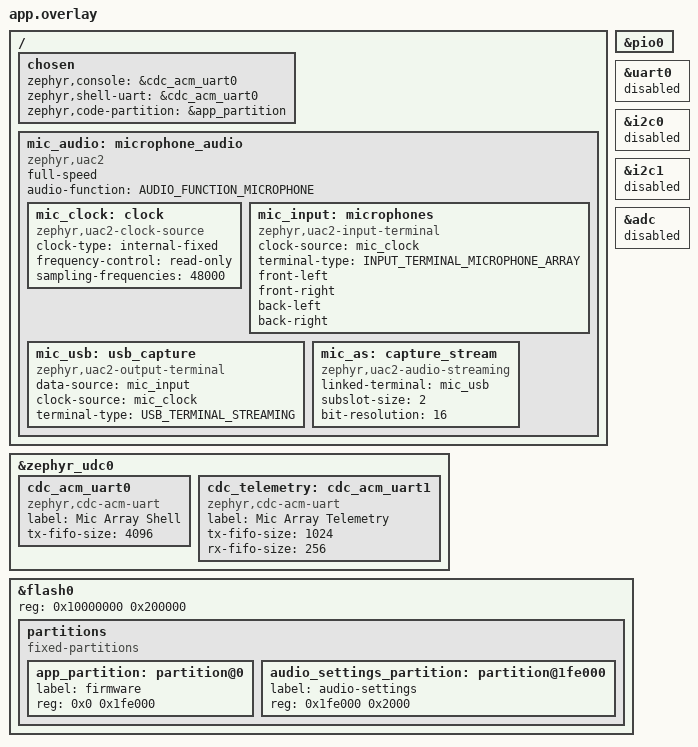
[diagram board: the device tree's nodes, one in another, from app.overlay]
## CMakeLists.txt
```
cmake_minimum_required(VERSION 3.20.0)
find_package(Zephyr REQUIRED HINTS $ENV{ZEPHYR_BASE})
project(pico2_mic_array)
target_include_directories(app PRIVATE src)
target_sources(app PRIVATE src/doa.c src/doa_control.c src/telemetry.c)
target_sources(app PRIVATE src/main.c src/dsp_parallel.c src/beamform.c src/noise_reduce.c src/nr_control.c src/usb_audio.c src/stream.c src/capture.c src/pdm_filter.c)

target_link_libraries(app PRIVATE m)

target_sources(app PRIVATE src/audio_settings.c)
```

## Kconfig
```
mainmenu "RP2354A microphone array"
source "Kconfig.zephyr"

config PICOSDK_USE_DMA
	default y
```

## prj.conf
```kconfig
CONFIG_GPIO=y
CONFIG_PIO_RPI_PICO=y
# The application owns the DMA controller: the generic driver cannot chain blocks.
CONFIG_DMA=n
CONFIG_USB_DEVICE_STACK_NEXT=y
CONFIG_UART_LINE_CTRL=y
CONFIG_SHELL=y
CONFIG_SHELL_BACKEND_SERIAL=y
CONFIG_SHELL_VT100_COLORS=n
CONFIG_SHELL_STACK_SIZE=4096
CONFIG_SHELL_BACKEND_SERIAL_TX_RING_BUFFER_SIZE=4096
# Emit machine telemetry in large batches rather than 30-byte printf fragments.
CONFIG_SHELL_PRINTF_BUFF_SIZE=512
CONFIG_MAIN_STACK_SIZE=4096
CONFIG_SPEED_OPTIMIZATIONS=y
CONFIG_BUILD_OUTPUT_UF2=y
# Keep capture/USB fault counters, but omit debug-only kernel assertions and
# spinlock ownership checks from the real-time audio build.
CONFIG_ASSERT=n
CONFIG_SPIN_VALIDATE=n

CONFIG_CRC=y

# Batch full-speed USB packets to reduce per-transfer workqueue overhead.
CONFIG_USBD_CDC_ACM_BUF_POOL=y
CONFIG_USBD_CDC_ACM_BUF_POOL_SIZE=1024
CONFIG_CDC_ACM_SERIAL_INITIALIZE_AT_BOOT=n
CONFIG_USBD_AUDIO2_CLASS=y

CONFIG_FPU=y
CONFIG_FPU_SHARING=y

CONFIG_FLASH=y
CONFIG_USE_DT_CODE_PARTITION=y
CONFIG_REBOOT=y
```

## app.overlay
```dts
#include <zephyr/dt-bindings/usb/audio.h>
/ {
	chosen {
		zephyr,console = &cdc_acm_uart0;
		zephyr,shell-uart = &cdc_acm_uart0;
	};
};

&zephyr_udc0 {
	cdc_acm_uart0: cdc_acm_uart0 {
		compatible = "zephyr,cdc-acm-uart";
		label = "Mic Array Shell";
		tx-fifo-size = <4096>;
	};
	cdc_telemetry: cdc_acm_uart1 {
		compatible = "zephyr,cdc-acm-uart";
		label = "Mic Array Telemetry";
		tx-fifo-size = <1024>;
		rx-fifo-size = <256>;
	};
};

mic_pio: &pio0 { status = "okay"; };
/* RP2354A: GP6=SCLK, GP7-GP10=DATA1-4, GP11-GP13=DIN/BCLK/LRC (U7). */
&uart0 { status = "disabled"; };
&i2c0 { status = "disabled"; };
&i2c1 { status = "disabled"; };
&adc { status = "disabled"; };

/ {
 mic_audio: microphone_audio {
  compatible = "zephyr,uac2";
  full-speed;
  audio-function = <AUDIO_FUNCTION_MICROPHONE>;
  mic_clock: clock {
   compatible = "zephyr,uac2-clock-source";
   clock-type = "internal-fixed";
   frequency-control = "read-only";
   sampling-frequencies = <48000>;
  };
  mic_input: microphones {
   compatible = "zephyr,uac2-input-terminal";
   clock-source = <&mic_clock>;
   terminal-type = <INPUT_TERMINAL_MICROPHONE_ARRAY>;
   /* USB quad channel slots; not physical array coordinates. */
   front-left;
   front-right;
   back-left;
   back-right;
  };
  mic_usb: usb_capture {
   compatible = "zephyr,uac2-output-terminal";
   data-source = <&mic_input>;
   clock-source = <&mic_clock>;
   terminal-type = <USB_TERMINAL_STREAMING>;
  };
  mic_as: capture_stream {
   compatible = "zephyr,uac2-audio-streaming";
   linked-terminal = <&mic_usb>;
   subslot-size = <2>;
   bit-resolution = <16>;
  };
 };
};

/ { chosen { zephyr,code-partition = &app_partition; }; };
/* RP2354A has 2 MiB in-package flash; reserve the final 8 KiB for settings. */
&flash0 {
 reg = <0x10000000 0x200000>;
 ranges = <0x0 0x10000000 0x200000>;
 partitions {
  compatible = "fixed-partitions";
  #address-cells = <1>; #size-cells = <1>;
  app_partition: partition@0 { label = "firmware"; reg = <0x0 0x1fe000>; };
  audio_settings_partition: partition@1fe000 { label = "audio-settings"; reg = <0x1fe000 0x2000>; };
 };
};
```

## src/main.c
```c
#include "capture.h"
#include "board_pins.h"
#include "pdm_filter.h"
#include "dsp_parallel.h"
#include "speaker_tone.h"
#include "stream.h"
#include "usb_audio.h"
#include "nr_control.h"
#include "doa.h"
#include <zephyr/shell/shell.h>
#include <pico/bootrom.h>
#include <zephyr/drivers/misc/pio_rpi_pico/pio_rpi_pico.h>
#include <hardware/clocks.h>
#include <hardware/timer.h>
#include <hardware/dma.h>
#include <hardware/pio_instructions.h>
#include <stdlib.h>
#include <string.h>

#define MAX_RECORD_FRAMES 16000
static struct pdm_filter filter;
static int16_t pcm[CAPTURE_FRAMES * MIC_CHANNELS];

#define RAW_BLOCKS 4
static union {
 int16_t recording[MAX_RECORD_FRAMES * MIC_CHANNELS];
 struct { uint32_t words[RAW_BLOCKS * CAPTURE_WORDS];
          int16_t pcm[RAW_BLOCKS * CAPTURE_FRAMES * MIC_CHANNELS]; } raw;
} diagnostic;
#define recording diagnostic.recording
#define raw_snapshot diagnostic.raw.words
#define raw_pcm diagnostic.raw.pcm
static atomic_t raw_request;
static unsigned raw_blocks;
static struct k_spinlock state_lock;
static struct {
	uint32_t target;
	uint32_t frames;
	uint32_t peak[MIC_CHANNELS];
	uint32_t max_process_us;
	uint32_t filter_blocks; uint64_t filter_total_us;
	bool ready;
	bool invalid;
} state;

static int cmd_boot(const struct shell *sh, size_t argc, char **argv)
{
	ARG_UNUSED(argc); ARG_UNUSED(argv);
	shell_print(sh, "Rebooting into USB BOOTSEL mode...");
	/* Allow the USB shell message to drain before disconnecting. */
	k_msleep(100);
	/* No activity GPIO; enable both mass-storage and picoboot interfaces. */
	reset_usb_boot(0, 0);
}

SHELL_CMD_ARG_REGISTER(boot, NULL, "Reboot into USB BOOTSEL mode for UF2 flashing",
		       cmd_boot, 1, 0);

static uint32_t i2s_probe[2048];
#if AUDIO_SPEAKER_DIAGNOSTICS
static uint32_t speaker_samples[32000];

/* Sample the actual output GPIOs internally, without adding jumper wires.
 * Each word packs eight chronological {LRCLK,BCLK,DIN} triples, MSB first. */
static int probe_init(PIO pio, size_t *probe_sm)
{
	const struct device *dev = DEVICE_DT_GET(DT_NODELABEL(mic_pio));
	int ret = pio_rpi_pico_allocate_sm(dev, probe_sm);
	if (ret) { return ret; }
	uint16_t instructions[] = {
		pio_encode_wait_gpio(false, SPEAKER_BCLK_PIN),
		pio_encode_wait_gpio(true, SPEAKER_BCLK_PIN),
		pio_encode_in(pio_pins, 3),
	};
	struct pio_program program = {.instructions = instructions, .length = 3, .origin = -1};
	if (!pio_can_add_program(pio, &program)) {
		pio_sm_unclaim(pio, *probe_sm);
		return -ENOMEM;
	}
	unsigned offset = pio_add_program(pio, &program);
	pio_sm_config config = pio_get_default_sm_config();
	sm_config_set_wrap(&config, offset, offset + 2);
	sm_config_set_in_pins(&config, SPEAKER_DATA_PIN);
	sm_config_set_in_shift(&config, false, true, 24);
	sm_config_set_fifo_join(&config, PIO_FIFO_JOIN_RX);
	pio_sm_init(pio, *probe_sm, offset, &config);
	return 0;
}

static int cmd_speaker_test(const struct shell *sh, size_t argc, char **argv)
{
	bool verify = strcmp(argv[0], "verify") == 0;
	unsigned frequency = 500;
	unsigned peak = 512;
	bool left_justified = false;
	if (argc > 1) {
		char *end;
		frequency = strtoul(argv[1], &end, 10);
		if (*end || frequency < 200 || frequency > 2000) { return -EINVAL; }
	}
	if (argc > 2) {
		char *end;
		peak = strtoul(argv[2], &end, 10);
		if (*end || peak > 512) { return -EINVAL; }
	}
	if (argc > 3) {
		if (strcmp(argv[3], "left") == 0) { left_justified = true; }
		else if (strcmp(argv[3], "i2s") != 0) { return -EINVAL; }
	}
	static bool initialized;
	static size_t speaker_sm;
	static unsigned format_offset[2];
	static bool probe_initialized;
	static size_t probe_sm;
	const struct device *dev = DEVICE_DT_GET(DT_NODELABEL(mic_pio));
	if (!device_is_ready(dev) || !atomic_get(&capture_stats.blocks)) {
		shell_error(sh, "Audio hardware not initialized");
		return -ENODEV;
	}
	PIO pio = pio_rpi_pico_get_pio(dev);
	if (!initialized) {
		int ret = pio_rpi_pico_allocate_sm(dev, &speaker_sm);
		if (ret) { return ret; }
		/* 32-bit stereo I2S. LR changes on the previous channel's LSB,
		 * one BCLK before the next MSB. Side-set bit0=BCLK, bit1=LRCLK. */
		uint16_t instructions[] = {
			pio_encode_out(pio_pins, 1) | pio_encode_sideset(2, 0),
			pio_encode_jmp_x_dec(0) | pio_encode_sideset(2, 1),
			pio_encode_out(pio_pins, 1) | pio_encode_sideset(2, 2),
			pio_encode_set(pio_x, 30) | pio_encode_sideset(2, 3),
			pio_encode_out(pio_pins, 1) | pio_encode_sideset(2, 2),
			pio_encode_jmp_x_dec(4) | pio_encode_sideset(2, 3),
			pio_encode_out(pio_pins, 1) | pio_encode_sideset(2, 0),
			pio_encode_set(pio_x, 30) | pio_encode_sideset(2, 1),
		};
		struct pio_program program = {
			.instructions = instructions, .length = ARRAY_SIZE(instructions), .origin = -1,
		};
		if (!pio_can_add_program(pio, &program)) {
			pio_sm_unclaim(pio, speaker_sm);
			return -ENOMEM;
		}
		unsigned offset = pio_add_program(pio, &program);
		format_offset[0] = offset;
		/* Diagnostic alternate format: align LRCLK with the MSB, as used
		 * by MAX98357B. Keep separate programs so switching is explicit. */
		uint16_t left_instructions[] = {
			pio_encode_out(pio_pins, 1) | pio_encode_sideset(2, 0),
			pio_encode_set(pio_x, 30) | pio_encode_sideset(2, 1),
			pio_encode_out(pio_pins, 1) | pio_encode_sideset(2, 0),
			pio_encode_jmp_x_dec(2) | pio_encode_sideset(2, 1),
			pio_encode_out(pio_pins, 1) | pio_encode_sideset(2, 2),
			pio_encode_set(pio_x, 30) | pio_encode_sideset(2, 3),
			pio_encode_out(pio_pins, 1) | pio_encode_sideset(2, 2),
			pio_encode_jmp_x_dec(6) | pio_encode_sideset(2, 3),
		};
		struct pio_program left_program = {
			.instructions = left_instructions, .length = 8, .origin = -1,
		};
		if (!pio_can_add_program(pio, &left_program)) {
			pio_remove_program(pio, &program, offset);
			pio_sm_unclaim(pio, speaker_sm);
			return -ENOMEM;
		}
		format_offset[1] = pio_add_program(pio, &left_program);
		pio_sm_config config = pio_get_default_sm_config();
		sm_config_set_wrap(&config, offset, offset + 7);
		sm_config_set_out_pins(&config, SPEAKER_DATA_PIN, 1);
		sm_config_set_sideset(&config, 2, false, false);
		sm_config_set_sideset_pins(&config, SPEAKER_BCLK_PIN);
		sm_config_set_out_shift(&config, false, true, 32);
		sm_config_set_fifo_join(&config, PIO_FIFO_JOIN_TX);
		sm_config_set_clkdiv(&config, (float)clock_get_hz(clk_sys) / (16000u * 128u));
		for (unsigned pin = SPEAKER_DATA_PIN; pin <= SPEAKER_LRC_PIN; pin++) { pio_gpio_init(pio, pin); }
		pio_sm_init(pio, speaker_sm, offset, &config);
		pio_sm_set_consecutive_pindirs(pio, speaker_sm, SPEAKER_DATA_PIN, 3, true);
		initialized = true;
	}
	int channel = dma_claim_unused_channel(false);
	if (channel < 0) { return -EBUSY; }
	int probe_channel = -1;
	if (verify) {
		if (!probe_initialized) {
			int ret = probe_init(pio, &probe_sm);
			if (ret) { dma_channel_unclaim(channel); return ret; }
			probe_initialized = true;
		}
		probe_channel = dma_claim_unused_channel(false);
		if (probe_channel < 0) { dma_channel_unclaim(channel); return -EBUSY; }
		pio_sm_clear_fifos(pio, probe_sm);
		pio_sm_restart(pio, probe_sm);
		unsigned bottom = (pio->sm[probe_sm].execctrl & PIO_SM0_EXECCTRL_WRAP_BOTTOM_BITS) >>
				  PIO_SM0_EXECCTRL_WRAP_BOTTOM_LSB;
		pio_sm_exec(pio, probe_sm, pio_encode_jmp(bottom));
		dma_channel_config probe_config = dma_channel_get_default_config(probe_channel);
		channel_config_set_transfer_data_size(&probe_config, DMA_SIZE_32);
		channel_config_set_read_increment(&probe_config, false);
		channel_config_set_write_increment(&probe_config, true);
		channel_config_set_dreq(&probe_config, pio_get_dreq(pio, probe_sm, false));
		dma_channel_configure(probe_channel, &probe_config, i2s_probe,
				      &pio->rxf[probe_sm], ARRAY_SIZE(i2s_probe), true);
		pio_sm_set_enabled(pio, probe_sm, true);
	}
	/* Identical L/R preserves the module's mono mix. Fade both ends and
	 * finish with 8 ms of silence; default peak 512 is about -36 dBFS. */
	uint32_t phase = 0;
	uint32_t phase_step = ((uint64_t)frequency << 32) / 16000u;
	for (unsigned n = 0; n < 16000; n++, phase += phase_step) {
		uint16_t sample = (uint16_t)speaker_tone_sample(phase, n, peak);
		speaker_samples[2 * n] = (uint32_t)sample << 16;
		speaker_samples[2 * n + 1] = (uint32_t)sample << 16;
	}
	pio_sm_set_enabled(pio, speaker_sm, false);
	pio_sm_clear_fifos(pio, speaker_sm);
	pio_sm_restart(pio, speaker_sm);
	unsigned wrap = format_offset[left_justified];
	pio_sm_set_wrap(pio, speaker_sm, wrap, wrap + 7);
	pio_sm_exec(pio, speaker_sm, pio_encode_jmp(wrap));
	pio_sm_exec(pio, speaker_sm, pio_encode_set(pio_x, 30));
	pio_sm_set_pins_with_mask(pio, speaker_sm, 0, BIT(SPEAKER_DATA_PIN) | BIT(SPEAKER_BCLK_PIN) | BIT(SPEAKER_LRC_PIN));
	dma_channel_config dma_config = dma_channel_get_default_config(channel);
	channel_config_set_transfer_data_size(&dma_config, DMA_SIZE_32);
	channel_config_set_read_increment(&dma_config, true);
	channel_config_set_write_increment(&dma_config, false);
	channel_config_set_dreq(&dma_config, pio_get_dreq(pio, speaker_sm, true));
	shell_print(sh, "Playing %u Hz for 1 second; PCM16 peak=%u; format=%s...",
		    frequency, peak, left_justified ? "left" : "i2s");
	dma_channel_configure(channel, &dma_config, &pio->txf[speaker_sm],
			      speaker_samples, ARRAY_SIZE(speaker_samples), true);
	pio_sm_set_enabled(pio, speaker_sm, true);
	int64_t deadline = k_uptime_get() + 1500;
	while (dma_channel_is_busy(channel) && k_uptime_get() < deadline) { k_msleep(5); }
	bool timed_out = dma_channel_is_busy(channel);
	k_msleep(2); /* Drain the FIFO and final shift register. */
	pio_sm_set_enabled(pio, speaker_sm, false);
	dma_channel_cleanup(channel);
	dma_channel_unclaim(channel);
	pio_sm_set_pins_with_mask(pio, speaker_sm, 0, BIT(SPEAKER_DATA_PIN) | BIT(SPEAKER_BCLK_PIN) | BIT(SPEAKER_LRC_PIN));
	if (verify) {
		bool complete = !dma_channel_is_busy(probe_channel);
		pio_sm_set_enabled(pio, probe_sm, false);
		dma_channel_cleanup(probe_channel);
		dma_channel_unclaim(probe_channel);
		if (!complete) { shell_error(sh, "I2S probe did not complete"); return -EIO; }
		shell_print(sh, "I2S_BEGIN %u", (unsigned)ARRAY_SIZE(i2s_probe));
		for (unsigned i = 0; i < ARRAY_SIZE(i2s_probe); i += 8) {
			shell_print(sh, "%08x%08x%08x%08x%08x%08x%08x%08x",
				i2s_probe[i], i2s_probe[i+1], i2s_probe[i+2], i2s_probe[i+3],
				i2s_probe[i+4], i2s_probe[i+5], i2s_probe[i+6], i2s_probe[i+7]);
		}
		shell_print(sh, "I2S_END");
	}
	if (timed_out) {
		shell_error(sh, "Speaker DMA timed out");
		return -ETIMEDOUT;
	}
	shell_print(sh, "Speaker test complete");
	return 0;
}

SHELL_STATIC_SUBCMD_SET_CREATE(speaker_commands,
	SHELL_CMD_ARG(test, NULL, "Play tone [Hz=500] [peak=512; 0..512] [i2s|left]", cmd_speaker_test, 1, 3),
	SHELL_CMD_ARG(verify, NULL, "Play tone and export GPIO samples [Hz] [peak] [i2s|left]", cmd_speaker_test, 1, 3),
	SHELL_SUBCMD_SET_END);
SHELL_CMD_REGISTER(speaker, &speaker_commands, "MAX98357A speaker", NULL);
#endif

static int cmd_stats(const struct shell *sh, size_t argc, char **argv)
{
	ARG_UNUSED(argc); ARG_UNUSED(argv);
	k_spinlock_key_t key = k_spin_lock(&state_lock);
	uint32_t peaks[MIC_CHANNELS];
	memcpy(peaks, state.peak, sizeof(peaks));
	uint32_t max_us = state.max_process_us;
	uint32_t fb = state.filter_blocks; uint64_t ft = state.filter_total_us;
	bool ready = state.ready;
	k_spin_unlock(&state_lock, key);
	shell_print(sh, "rate=%u channels=4 ready=%u blocks=%ld dropped=%ld faults=%ld max_process_us=%u",
		capture_stats.sample_rate, ready, (long)atomic_get(&capture_stats.blocks),
		(long)atomic_get(&capture_stats.dropped), (long)atomic_get(&capture_stats.faults), max_us);
	shell_print(sh, "PDM_PROFILE blocks=%u mean_us=%u", fb, fb ? (unsigned)(ft/fb) : 0);
	uint32_t local_us,remote_us,worker_status;dsp_parallel_profile(&local_us,&remote_us,&worker_status);
	shell_print(sh,"DSP_PIPELINE cores=2 fir_core0_us=%u cic_core1_us=%u worker_status=%u",local_us,remote_us,worker_status);
	shell_print(sh, "peak_pcm16=%u,%u,%u,%u", peaks[0], peaks[1], peaks[2], peaks[3]);
	return 0;
}

static int cmd_record(const struct shell *sh, size_t argc, char **argv)
{
	ARG_UNUSED(argc);
	char *end;
	unsigned long ms = strtoul(argv[1], &end, 10);
	if (*end || ms < 1 || ms > MAX_RECORD_FRAMES * 1000u / PCM_SAMPLE_RATE) {
		shell_error(sh, "Duration must be 1..%u ms (RAM diagnostic limit)", MAX_RECORD_FRAMES * 1000u / PCM_SAMPLE_RATE);
		return -EINVAL;
	}
	k_spinlock_key_t key = k_spin_lock(&state_lock);
	if (!state.ready || atomic_get(&capture_stats.faults) ||
	    (!state.invalid && state.frames < state.target)) {
		k_spin_unlock(&state_lock, key);
		shell_error(sh, "Capture warming up, faulted, or recording busy");
		return -EBUSY;
	}
	state.frames = 0;
	state.target = MIN((uint64_t)ms * capture_stats.sample_rate / 1000u, MAX_RECORD_FRAMES);
	state.invalid = false;
	k_spin_unlock(&state_lock, key);
	shell_print(sh, "RECORDING");
	return 0;
}

static int cmd_status(const struct shell *sh, size_t argc, char **argv)
{
	ARG_UNUSED(argc); ARG_UNUSED(argv);
	k_spinlock_key_t key = k_spin_lock(&state_lock);
	uint32_t frames = state.frames, target = state.target;
	bool invalid = state.invalid;
	k_spin_unlock(&state_lock, key);
	shell_print(sh, "RECORD %s %u %u", invalid ? "INVALID" :
		(target == 0 ? "EMPTY" : (frames == target ? "DONE" : "BUSY")), frames, target);
	return 0;
}

static int cmd_dump(const struct shell *sh, size_t argc, char **argv)
{
	ARG_UNUSED(argc); ARG_UNUSED(argv);
	k_spinlock_key_t key = k_spin_lock(&state_lock);
	uint32_t frames = state.frames;
	bool valid = state.target && frames == state.target && !state.invalid;
	k_spin_unlock(&state_lock, key);
	if (!valid) {
		shell_error(sh, "No complete valid recording; use mic record <ms> then mic status");
		return -EAGAIN;
	}
	/* Shell commands are serialized. A new record command cannot overwrite
	 * this completed buffer while dump is running. Capture keeps running. */
	static const char hex[] = "0123456789abcdef";
	char line[257];
	const uint8_t *bytes = (const uint8_t *)recording;
	size_t length = frames * MIC_CHANNELS * sizeof(int16_t);
	shell_print(sh, "PCM_BEGIN %u 4 %u", capture_stats.sample_rate, frames);
	for (size_t n = 0; n < length; n += 128) {
		size_t chunk = MIN(length - n, 128);
		for (size_t j = 0; j < chunk; j++) {
			line[2 * j] = hex[bytes[n + j] >> 4];
			line[2 * j + 1] = hex[bytes[n + j] & 15];
		}
		line[2 * chunk] = 0;
		shell_print(sh, "%s", line);
	}
	shell_print(sh, "PCM_END");
	return 0;
}

static int cmd_stream(const struct shell *sh, size_t argc, char **argv)
{
	ARG_UNUSED(argc);
	char *end;
	unsigned long seconds = strtoul(argv[1], &end, 10);
	if (*end || seconds < 1 || seconds > 3600) { return -EINVAL; }
	k_spinlock_key_t key = k_spin_lock(&state_lock);
	bool ready = state.ready;
	k_spin_unlock(&state_lock, key);
	if (!ready || atomic_get(&capture_stats.faults)) { return -EAGAIN; }
	return stream_run(sh, seconds);
}

static int cmd_raw(const struct shell *sh, size_t argc, char **argv)
{
	ARG_UNUSED(argc); ARG_UNUSED(argv);
	k_spinlock_key_t state_key = k_spin_lock(&state_lock);
	if (state.frames < state.target && !state.invalid) {
		k_spin_unlock(&state_lock, state_key); return -EBUSY;
	}
	state.target = 0; state.frames = 0;
	k_spin_unlock(&state_lock, state_key);
	if (atomic_get(&capture_stats.faults) || !atomic_get(&capture_stats.blocks)) {
		return -EIO;
	}
	uint32_t edges, elapsed_us;
	int ret = capture_clock_measure(&edges, &elapsed_us);
	if (ret) { return ret; }
	shell_print(sh, "PDM_CLOCK edges=%u elapsed_us=%u", edges, elapsed_us);
	raw_blocks = 0;
	atomic_set(&raw_request, 1);
	int64_t deadline = k_uptime_get() + 500;
	while (atomic_get(&raw_request) == 1 && k_uptime_get() < deadline) { k_msleep(5); }
	if (atomic_get(&raw_request) != 0) {
		atomic_set(&raw_request, 0);
		shell_error(sh, "Raw capture incomplete or discontinuous");
		return -EIO;
	}
	shell_print(sh, "RAW_BEGIN %u %u %u", PDM_CLOCK_HZ, PDM_DECIMATION,
		    (unsigned)ARRAY_SIZE(raw_snapshot));
	for (unsigned i = 0; i < ARRAY_SIZE(raw_snapshot); i += 8) {
		shell_print(sh, "%08x%08x%08x%08x%08x%08x%08x%08x",
			raw_snapshot[i], raw_snapshot[i+1], raw_snapshot[i+2], raw_snapshot[i+3],
			raw_snapshot[i+4], raw_snapshot[i+5], raw_snapshot[i+6], raw_snapshot[i+7]);
	}
	shell_print(sh, "RAW_END");
	shell_print(sh, "RAW_PCM_BEGIN %u", (unsigned)ARRAY_SIZE(raw_pcm));
	for (unsigned i = 0; i < ARRAY_SIZE(raw_pcm); i += 8) {
		shell_print(sh, "%04x%04x%04x%04x%04x%04x%04x%04x",
			(uint16_t)raw_pcm[i], (uint16_t)raw_pcm[i+1], (uint16_t)raw_pcm[i+2], (uint16_t)raw_pcm[i+3],
			(uint16_t)raw_pcm[i+4], (uint16_t)raw_pcm[i+5], (uint16_t)raw_pcm[i+6], (uint16_t)raw_pcm[i+7]);
	}
	shell_print(sh, "RAW_PCM_END");
	ret = capture_phase_read(i2s_probe, ARRAY_SIZE(i2s_probe));
	if (ret) { return ret; }
	shell_print(sh, "PHASE_BEGIN %u", (unsigned)ARRAY_SIZE(i2s_probe));
	for (unsigned i = 0; i < ARRAY_SIZE(i2s_probe); i += 8) {
		shell_print(sh, "%08x%08x%08x%08x%08x%08x%08x%08x",
			i2s_probe[i], i2s_probe[i+1], i2s_probe[i+2], i2s_probe[i+3],
			i2s_probe[i+4], i2s_probe[i+5], i2s_probe[i+6], i2s_probe[i+7]);
	}
	shell_print(sh, "PHASE_END");
	ret = capture_clock_trace(i2s_probe, ARRAY_SIZE(i2s_probe));
	if (ret) { return ret; }
	shell_print(sh, "CLOCK_TRACE_BEGIN %u %u", (unsigned)ARRAY_SIZE(i2s_probe), clock_get_hz(clk_sys));
	for (unsigned i = 0; i < ARRAY_SIZE(i2s_probe); i += 8) {
		shell_print(sh, "%08x%08x%08x%08x%08x%08x%08x%08x",
			i2s_probe[i], i2s_probe[i+1], i2s_probe[i+2], i2s_probe[i+3],
			i2s_probe[i+4], i2s_probe[i+5], i2s_probe[i+6], i2s_probe[i+7]);
	}
	shell_print(sh, "CLOCK_TRACE_END");
	return 0;
}

SHELL_STATIC_SUBCMD_SET_CREATE(mic_commands,
	SHELL_CMD_ARG(stream, NULL, "Stream binary PCM for 1..3600 seconds (host tool)", cmd_stream, 2, 0),
	SHELL_CMD(stats, NULL, "Capture health and recent per-channel peaks", cmd_stats),
	SHELL_CMD_ARG(record, NULL, "Record 1..333 ms of four-channel PCM (RAM limit)", cmd_record, 2, 0),
	SHELL_CMD(status, NULL, "Recording status", cmd_status),
	SHELL_CMD(dump, NULL, "Export completed recording as framed PCM16 hex", cmd_dump),
	SHELL_CMD(raw, NULL, "Measure GPIO clock and export raw PDM plus matching PCM", cmd_raw),
	SHELL_SUBCMD_SET_END);
SHELL_CMD_REGISTER(mic, &mic_commands, "RP2354A microphone array", NULL);

__ramfunc __attribute__((optimize("O3"))) int main(void)
{
	/* Capture outranks shell work. Any continuity failure stops acquisition,
     * allowing shell recovery instead of an overloaded conversion loop. */
	k_thread_priority_set(k_current_get(), 2);
	audio_control_restore();
	pdm_filter_init(&filter);
	int ret = usb_audio_init();
	if (ret) { return ret; }
	ret = dsp_parallel_init();
	if(ret){printk("DSP core launch failed: %d\n",ret);return ret;}
	ret = capture_start();
	if (ret) {
		atomic_inc(&capture_stats.faults);
		printk("Capture initialization failed: %d; reboot required\n", ret);
		return ret;
	}
	uint32_t expected = 0;
	uint32_t warmup = 48; /* >100 ms, including microphone and CIC settling. */
	while (true) {
		struct capture_block *block;
		if (capture_read(&block, K_MSEC(100)) != 0) {
			if (atomic_get(&capture_stats.faults)) {
				k_spinlock_key_t key = k_spin_lock(&state_lock);
				state.ready = false;
				if (state.frames < state.target) { state.invalid = true; }
				k_spin_unlock(&state_lock, key);
			}
			continue;
		}
		uint32_t start = k_cycle_get_32();
		if (atomic_get(&capture_stats.faults)) {
			capture_release(block);
			k_spinlock_key_t key = k_spin_lock(&state_lock);
			state.ready = false;
			if (state.frames < state.target) { state.invalid = true; }
			k_spin_unlock(&state_lock, key);
			continue;
		}
		if (block->sequence != expected) {
            /* Lost input is fatal: never conceal it with repeated warmup silence. */
            if(atomic_get(&raw_request)==1)atomic_set(&raw_request,-1);
            capture_fail();continue;
        }
        expected=block->sequence+1;
		uint32_t filter_start = k_cycle_get_32();
		/* On timeout retain this DMA block: core 1 may still be reading it. */
		struct capture_block *completed;
        if(dsp_parallel_process(&filter,block,pcm,&completed)){capture_fail();continue;}
        if(!completed)continue;
        block=completed;
		uint32_t filter_us = k_cyc_to_us_floor32(k_cycle_get_32()-filter_start);
		if (!warmup) {
			stream_push(pcm, block->sequence);
            doa_feed(pcm,block->sequence,block->end_us);
			usb_audio_push(nr_apply(pcm), block->sequence);
		}
		if (atomic_get(&raw_request) == 1) {
			memcpy(raw_snapshot + raw_blocks * CAPTURE_WORDS, block->words,
			       CAPTURE_WORDS * sizeof(uint32_t));
			memcpy(raw_pcm + raw_blocks * CAPTURE_FRAMES * MIC_CHANNELS, pcm, sizeof(pcm));
			if (++raw_blocks == RAW_BLOCKS) { atomic_set(&raw_request, 0); }
		}
		capture_release(block);
		uint32_t peaks[MIC_CHANNELS] = {0};
		for (unsigned f = 0; f < CAPTURE_FRAMES; f++) {
			for (unsigned c = 0; c < MIC_CHANNELS; c++) {
				int32_t sample = pcm[f * MIC_CHANNELS + c];
				peaks[c] = MAX(peaks[c], (uint32_t)abs(sample));
			}
		}
		k_spinlock_key_t key = k_spin_lock(&state_lock);
		if (warmup) {
			warmup--;
		} else {
			state.ready = !atomic_get(&capture_stats.faults);
			memcpy(state.peak, peaks, sizeof(peaks));
			if (state.frames < state.target && !state.invalid) {
				uint32_t count = MIN(CAPTURE_FRAMES, state.target - state.frames);
				memcpy(recording + state.frames * MIC_CHANNELS, pcm,
				       count * MIC_CHANNELS * sizeof(int16_t));
				state.frames += count;
			}
		}
		uint32_t elapsed = k_cyc_to_us_floor32(k_cycle_get_32() - start);
		state.max_process_us = MAX(state.max_process_us, elapsed);
		state.filter_blocks++; state.filter_total_us += filter_us;
		k_spin_unlock(&state_lock, key);
		k_yield();
	}
}
```

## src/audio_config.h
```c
#ifndef AUDIO_CONFIG_H
#define AUDIO_CONFIG_H
#define PCM_SAMPLE_RATE 48000u
/* Passive-speaker diagnostics are deferred in this microphone profile. */
#define AUDIO_SPEAKER_DIAGNOSTICS 0
#endif
```

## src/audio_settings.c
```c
#include "audio_settings.h"
#include "nr_control.h"
#include "dsp_parallel.h"
#include "capture.h"
#include "usb_audio.h"
#include <zephyr/kernel.h>
#include <zephyr/drivers/flash.h>
#include <zephyr/storage/flash_map.h>
#include <zephyr/sys/crc.h>
#include <zephyr/sys/reboot.h>
#include <stddef.h>
#include <string.h>
#include <errno.h>
#include <math.h>
#define OFFSET PARTITION_OFFSET(audio_settings_partition)
#define MAGIC 0x4d494341u
BUILD_ASSERT(PARTITION_SIZE(audio_settings_partition)==8192);
BUILD_ASSERT(PARTITION_OFFSET(audio_settings_partition)+PARTITION_SIZE(audio_settings_partition)==DT_REG_SIZE(DT_CHOSEN(zephyr_flash)));
BUILD_ASSERT(sizeof(struct audio_config_record)<=768);
static const struct device *const flash=PARTITION_DEVICE(audio_settings_partition);
static struct audio_config_record stored,pending;
static bool loaded;static unsigned active_slot;
static atomic_t saving,save_error,dirty=ATOMIC_INIT(1);
void audio_settings_changed(void){atomic_set(&dirty,1);}
bool audio_settings_saving(void){return atomic_get(&saving)!=0;}
int audio_settings_error(void){return atomic_get(&save_error);}
static bool valid(const struct audio_config_record *r){
 for(unsigned i=0;i<129;i++)if(!isfinite(r->noise[i]) || r->noise[i]<0)return false;
 return r->learned<=1 && r->magic==MAGIC && r->version==1 && r->crc==crc32_ieee((const uint8_t *)r,offsetof(struct audio_config_record,crc)) &&
 r->nr_mode<=2 && (r->hum==0 || r->hum==50 || r->hum==60) && r->channel>=1 && r->channel<=4 && r->beam_mode<=2 && r->azimuth<3600 && r->elevation<=900;
}
bool audio_settings_load(struct audio_config_record *record){
 struct audio_config_record slots[2];loaded=false;
 if(!device_is_ready(flash))return false;
 for(unsigned i=0;i<2;i++){
  if(flash_read(flash,OFFSET+i*4096,&slots[i],sizeof(slots[i])) || !valid(&slots[i]))continue;
  if(!loaded || (int32_t)(slots[i].generation-stored.generation)>0){stored=slots[i];active_slot=i;loaded=true;}
 }
 atomic_set(&dirty,!loaded);
 if(loaded)*record=stored;
 return loaded;
}
static void snapshot(struct audio_config_record *r){
 struct output_status s;output_status_get(&s);memset(r,0,sizeof(*r));
 r->magic=MAGIC;r->version=1;r->generation=loaded?stored.generation+1:1;
 r->nr_mode=s.nr_mode;r->hum=s.hum;r->channel=s.channel?s.channel:1;
 r->beam_mode=s.beam_mode;r->azimuth=s.beam_mode==2?s.azimuth_tdeg:0;r->elevation=s.beam_mode==2?s.elevation_tdeg:900;
 noise_profile_copy(&r->learned,r->noise);
 r->crc=crc32_ieee((const uint8_t *)r,offsetof(struct audio_config_record,crc));
}
bool audio_settings_match(void){return loaded && !atomic_get(&dirty);}

static void save_work(struct k_work *work){
 ARG_UNUSED(work);
 /* All flash users on core 1 must park in SRAM before XIP is suspended.
  * Capture is intentionally stopped; flash changes are followed by a reboot. */
 if(usb_audio_active()){atomic_set(&save_error,-EBUSY);atomic_clear(&saving);return;}
 capture_fail();
 if(dsp_parallel_park()){sys_reboot(SYS_REBOOT_COLD);return;}
 unsigned key=irq_lock();
 static uint8_t page[768];memset(page,0xff,sizeof(page));memcpy(page,&pending,sizeof(pending));
 unsigned slot=loaded?(active_slot^1):0;
 int error=flash_erase(flash,OFFSET+slot*4096,4096);
 if(!error)error=flash_write(flash,OFFSET+slot*4096,page,sizeof(page));
 static struct audio_config_record check;
 if(!error)error=flash_read(flash,OFFSET+slot*4096,&check,sizeof(check));
 /* An interrupted/failed save leaves the older CRC-checked slot intact. */
 if(!error && valid(&check) && !memcmp(&check,&pending,sizeof(check)))stored=check;
 ARG_UNUSED(key);sys_reboot(SYS_REBOOT_COLD);
}
K_WORK_DELAYABLE_DEFINE(save_job,save_work);
int audio_settings_save_restart(void){
 if(usb_audio_active())return -EBUSY;
 struct output_status s;output_status_get(&s);if(s.pending || s.fade_left || s.learn_left || noise_control_pending())return -EAGAIN;
 if(!atomic_cas(&saving,0,1))return -EBUSY;
 atomic_clear(&save_error);snapshot(&pending);
 if(!valid(&pending)){atomic_clear(&saving);return -EINVAL;}
 k_work_reschedule(&save_job,K_MSEC(500));return 0;
}
```

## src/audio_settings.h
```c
#ifndef AUDIO_SETTINGS_H
#define AUDIO_SETTINGS_H
#include <stdint.h>
#include <stdbool.h>
struct audio_config_record {uint32_t magic,version,generation,nr_mode,hum,channel,beam_mode,azimuth,elevation,learned;float noise[129];uint32_t crc;};
bool audio_settings_load(struct audio_config_record *record);
int audio_settings_save_restart(void);
bool audio_settings_match(void);
void audio_settings_changed(void);
bool audio_settings_saving(void);
int audio_settings_error(void);
#endif
```

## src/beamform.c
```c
#include "beamform.h"
#include <math.h>
#include <string.h>
#ifdef __ZEPHYR__
#include <zephyr/linker/section_tags.h>
#define BF_HOT __ramfunc __attribute__((optimize("O3")))
#else
#define BF_HOT
#endif

#define PI 3.14159265358979323846f
int beamform_prepare(struct beam_bank *b,int mode,unsigned azimuth,unsigned elevation)
{
 if(mode<BF_OFF || mode>BF_MANUAL || azimuth>=3600 || elevation>900)return -1;
 memset(b,0,sizeof(*b));b->mode=mode;
 b->azimuth_tdeg=mode==BF_MANUAL?azimuth:0;b->elevation_tdeg=mode==BF_MANUAL?elevation:900;
 float ux=0,uy=0;
 if(mode==BF_MANUAL && elevation<900){
  float scale=.025f*48000.f/343.f*cosf(elevation*PI/1800.f);
  ux=scale*cosf(azimuth*PI/1800.f);uy=scale*sinf(azimuth*PI/1800.f);
 }
 const float projection[4]={uy,-ux,-uy,ux};
 for(unsigned c=0;c<4;c++){
  float delay=BF_COMMON_DELAY+projection[c];
  if(fabsf(delay-BF_COMMON_DELAY)<.00001f)delay=BF_COMMON_DELAY;
  b->delay[c]=mode==BF_OFF?0:delay;
  unsigned whole=(unsigned)floorf(delay);float fraction=delay-whole;
  b->integral[c]=whole-BF_TAPS/2;
  if(fraction<.00001f){b->coefficient[c][BF_TAPS/2]=16384;continue;}
  float sum=0,coeff[BF_TAPS];
  for(unsigned k=0;k<BF_TAPS;k++){
   float x=(float)k-BF_TAPS/2-fraction;
   float sinc=fabsf(x)<.00001f?1:sinf(PI*x)/(PI*x);
   float window=.54f-.46f*cosf(2*PI*k/(BF_TAPS-1));
   coeff[k]=sinc*window;sum+=coeff[k];
  }
  int32_t total=0;
  for(unsigned k=0;k<BF_TAPS;k++){b->coefficient[c][k]=(int32_t)lroundf(coeff[k]/sum*16384.f);total+=b->coefficient[c][k];}
  b->coefficient[c][BF_TAPS/2]+=16384-total;
  for(unsigned k=0;k<BF_TAPS/2;k++){int16_t t=b->coefficient[c][k];b->coefficient[c][k]=b->coefficient[c][BF_TAPS-1-k];b->coefficient[c][BF_TAPS-1-k]=t;}
 }
 return 0;
}
void beamform_init(struct beamformer *s){memset(s,0,sizeof(*s));}
void beamform_target(struct beamformer *s,const struct beam_bank *b)
{s->target=*b;s->fade_left=BF_FADE_FRAMES;}
static BF_HOT float render(const struct beamformer *s,const struct beam_bank *b,unsigned channel)
{
 if(b->mode==BF_OFF)return s->history[channel][s->position];
 float sum=0;
 if(b->mode==BF_BROADSIDE || b->elevation_tdeg==900){
  for(unsigned c=0;c<4;c++)sum+=s->history[c][(s->position-BF_COMMON_DELAY)&(BF_HISTORY-1)];
 }else{
  int64_t accumulator=0;
  for(unsigned c=0;c<4;c++){
   const int16_t *samples=s->history[c]+s->position+BF_HISTORY-b->integral[c]-(BF_TAPS-1);
#if defined(__arm__) && defined(__ARM_FEATURE_DSP)
   const int16_t *coeff=b->coefficient[c];unsigned count=(BF_TAPS-1)/2;uint32_t x,y;
   __asm__ volatile("1: ldr %2, [%4], #4\n"
                    "ldr %3, [%5], #4\n"
                    "smlald %Q0, %R0, %2, %3\n"
                    "subs %1, %1, #1\n"
                    "bne 1b"
                    : "+&r"(accumulator), "+&r"(count), "=&r"(x), "=&r"(y), "+&r"(samples), "+&r"(coeff)
                    : : "cc", "memory");
   accumulator+=(int32_t)*samples**coeff;
#else
   for(unsigned k=0;k<BF_TAPS;k++)accumulator+=(int32_t)samples[k]*b->coefficient[c][k];
#endif
  }
  return (float)(int32_t)(accumulator>>2)*(1.f/16384.f);
 }
 return sum*.25f;
}
static int16_t rounded(float value)
{if(value>=32767)return 32767;if(value<=-32768)return -32768;return (int16_t)(value+(value>=0?.5f:-.5f));}
BF_HOT void beamform_process(struct beamformer *s,const int16_t *input,int16_t *output,size_t frames)
{
 for(size_t n=0;n<frames;n++){
  for(unsigned c=0;c<4;c++){s->history[c][s->position]=input[4*n+c];s->history[c][s->position+BF_HISTORY]=input[4*n+c];}
  float old=0,next=0;
  if(s->current.mode!=BF_OFF)old=render(s,&s->current,0);
  if(s->fade_left && s->target.mode!=BF_OFF)next=render(s,&s->target,0);
  if(!s->fade_left){
   if(s->current.mode==BF_OFF){for(unsigned c=0;c<4;c++)output[4*n+c]=input[4*n+c];}
   else {int16_t value=rounded(old);for(unsigned c=0;c<4;c++)output[4*n+c]=value;}
   s->position=(s->position+1)&(BF_HISTORY-1);continue;
  }
  float alpha=s->fade_left?(float)(BF_FADE_FRAMES-s->fade_left+1)/BF_FADE_FRAMES:0;
  for(unsigned c=0;c<4;c++){
   float a=s->current.mode==BF_OFF?s->history[c][s->position]:old;
   float b=s->target.mode==BF_OFF?s->history[c][s->position]:next;
   output[4*n+c]=rounded(s->fade_left?a+(b-a)*alpha:a);
  }
  if(s->fade_left && !--s->fade_left)s->current=s->target;
  s->position=(s->position+1)&(BF_HISTORY-1);
 }
}

BF_HOT void beamform_broadside(const int16_t *input, int16_t *output, size_t frames)
{
 for (size_t n=0;n<frames;n++) {
  int32_t sum=0;
  for(int c=0;c<4;c++)sum+=input[4*n+c];
  /* Round ties away from zero. A four-input average cannot overflow PCM16. */
  int16_t value=(sum>=0?(sum+2)/4:(sum-2)/4);
  for(int c=0;c<4;c++)output[4*n+c]=value;
 }
}
```

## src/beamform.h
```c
#ifndef BEAMFORM_H
#define BEAMFORM_H
#include <stddef.h>
#include <stdint.h>
#define BF_TAPS 21
#define BF_HISTORY 32
#define BF_COMMON_DELAY 14
#define BF_FADE_FRAMES 960
enum beam_mode { BF_OFF, BF_BROADSIDE, BF_MANUAL };
struct beam_bank {
 int mode;unsigned azimuth_tdeg,elevation_tdeg;
 unsigned integral[4];float delay[4]; int16_t coefficient[4][BF_TAPS+1];
};
struct beamformer {
 int16_t history[4][BF_HISTORY*2];unsigned position,fade_left;
 struct beam_bank current,target;
};
int beamform_prepare(struct beam_bank *bank,int mode,unsigned azimuth_tdeg,unsigned elevation_tdeg);
void beamform_init(struct beamformer *state);
void beamform_target(struct beamformer *state,const struct beam_bank *bank);
void beamform_process(struct beamformer *state,const int16_t *input,int16_t *output,size_t frames);
/* Equal-radius planar array: broadside needs zero relative sample delays.
 * Output is duplicated into four UAC slots, with unity coherent gain. */
void beamform_broadside(const int16_t *input, int16_t *output, size_t frames);
#endif
```

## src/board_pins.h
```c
#ifndef MIC_ARRAY_BOARD_PINS_H
#define MIC_ARRAY_BOARD_PINS_H
/* RP2354A board, U5 RP2354A QFN-60. GPIO numbers are not package pin numbers. */
#define MIC_CLOCK_PIN 6u       /* SCLK: U5 pin 9 */
#define MIC_DATA1_PIN 7u       /* DATA1 / U1: U5 pin 10 */
#define MIC_DATA2_PIN 8u       /* DATA2 / U2: U5 pin 12 */
#define MIC_DATA3_PIN 9u       /* DATA3 / U3: U5 pin 13 */
#define MIC_DATA4_PIN 10u      /* DATA4 / U4: U5 pin 14 */
#define SPEAKER_DATA_PIN 11u   /* DIN / U7 pin 3: U5 pin 15 */
#define SPEAKER_BCLK_PIN 12u   /* BCLK / U7 pin 4: U5 pin 16 */
#define SPEAKER_LRC_PIN 13u    /* LRC / U7 pin 5: U5 pin 17 */
#if MIC_DATA2_PIN != MIC_DATA1_PIN+1 || MIC_DATA3_PIN != MIC_DATA1_PIN+2 || MIC_DATA4_PIN != MIC_DATA1_PIN+3
#error "PDM parallel input requires four consecutive data GPIOs"
#endif
#if SPEAKER_BCLK_PIN != SPEAKER_DATA_PIN+1 || SPEAKER_LRC_PIN != SPEAKER_BCLK_PIN+1
#error "I2S output and diagnostic probe require consecutive DIN/BCLK/LRC GPIOs"
#endif
#endif
```

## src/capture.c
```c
#include "capture.h"
#include "board_pins.h"
#include <zephyr/device.h>
#include <zephyr/drivers/misc/pio_rpi_pico/pio_rpi_pico.h>
#include <zephyr/drivers/reset.h>
#include <zephyr/irq.h>
#include <hardware/clocks.h>
#include <hardware/dma.h>
#include <hardware/timer.h>
#include <hardware/pio_instructions.h>

#define CLOCK_PIN MIC_CLOCK_PIN
#define DATA_PIN MIC_DATA1_PIN
#define DMA_NODE DT_NODELABEL(dma)
#define DMA_IRQ_INDEX 2
#define DMA_IRQ DT_IRQ_BY_IDX(DMA_NODE, DMA_IRQ_INDEX, irq)

BUILD_ASSERT(!IS_ENABLED(CONFIG_DMA), "Capture requires exclusive DMA controller ownership");
/* Ring each DMA destination within its own 4 KiB data area. If an IRQ is
 * delayed past the chaining deadline, hardware must not write beyond the
 * buffer before we can detect and stop the stream. Metadata lives outside
 * that ring. Padding costs RAM but keeps every buffer independently owned. */
static uint32_t raw_data[CAPTURE_BUFFERS][1024] __aligned(4096);
K_MEM_SLAB_DEFINE(raw_pool, sizeof(struct capture_block), CAPTURE_BUFFERS, 4);

static int allocate_raw(struct capture_block **block)
{
	int ret = k_mem_slab_alloc(&raw_pool, (void **)block, K_NO_WAIT);
	if (!ret) {
		size_t index = ((char *)*block - raw_pool.buffer) / sizeof(struct capture_block);
		(*block)->words = raw_data[index];
	}
	return ret;
}
K_MSGQ_DEFINE(raw_queue, sizeof(struct capture_block *), CAPTURE_BUFFERS, 4);
struct capture_stats capture_stats;
static PIO pio;
static size_t sm;
static int channels[2] = {-1, -1};
static struct capture_block *active[2];
static uint32_t channel_mask;
static uint32_t sequence;
static unsigned expected;
static bool counter_initialized;
static size_t counter_sm;
static unsigned counter_offset;

static void fault_stop(void)
{
	pio_sm_set_enabled(pio, sm, false);
	dma_hw->inte2 &= ~channel_mask;
	/* Abort is deliberately deferred to reboot; no waiting in the ISR. */
	pio_sm_set_pins_with_mask(pio, sm, 0, BIT(CLOCK_PIN));
	atomic_inc(&capture_stats.faults);
}

void capture_fail(void)
{
 unsigned key=irq_lock();fault_stop();irq_unlock(key);
}

static void dma_isr(const void *unused)
{
	ARG_UNUSED(unused);
	uint32_t pending = dma_hw->ints2 & channel_mask;
	if (pending != BIT(channels[expected])) {
		/* Both completed means the rearm deadline was missed. Do not silently
		 * continue with reordered blocks or a stopped microphone clock. */
		dma_hw->ints2 = pending;
		fault_stop();
		return;
	}
	unsigned slot = expected;
	unsigned ch = channels[slot];
	dma_hw->ints2 = BIT(ch);
	if ((dma_hw->ch[ch].ctrl_trig & DMA_CH0_CTRL_TRIG_AHB_ERROR_BITS) ||
	    (pio->fdebug & BIT(PIO_FDEBUG_RXSTALL_LSB + sm))) {
		fault_stop();
		return;
	}
	struct capture_block *done = active[slot];
	struct capture_block *next;
	done->sequence = sequence++;
 done->end_us=time_us_32();
	atomic_inc(&capture_stats.blocks);
	if (allocate_raw(&next) != 0) {
		/* Reuse only this finished block; never overwrite a consumer buffer. */
		next = done;
		atomic_inc(&capture_stats.dropped);
	} else if (k_msgq_put(&raw_queue, &done, K_NO_WAIT) != 0) {
		k_mem_slab_free(&raw_pool, done);
		atomic_inc(&capture_stats.dropped);
	}
	active[slot] = next;
	dma_channel_set_write_addr(ch, next->words, false);
	dma_channel_set_trans_count(ch, CAPTURE_WORDS, false);
	expected ^= 1u;
}

int capture_start(void)
{
	const struct device *dev = DEVICE_DT_GET(DT_NODELABEL(mic_pio));
	const struct reset_dt_spec reset = RESET_DT_SPEC_GET(DMA_NODE);
	if (!device_is_ready(dev) || !device_is_ready(reset.dev)) { return -ENODEV; }
	int ret = pio_rpi_pico_allocate_sm(dev, &sm);
	if (ret) { return ret; }
	pio = pio_rpi_pico_get_pio(dev);
	/* LR=GND selects the right channel, driven during CLOCK low. Sample
	 * late in the low half, before the rising edge releases DATA. */
	uint16_t instructions[] = {
		pio_encode_nop() | pio_encode_sideset(1, 0) | pio_encode_delay(3),
		pio_encode_in(pio_pins, 4) | pio_encode_sideset(1, 0),
		pio_encode_nop() | pio_encode_sideset(1, 1) | pio_encode_delay(4),
	};
	struct pio_program program = {.instructions = instructions, .length = 3, .origin = -1};
	if (!pio_can_add_program(pio, &program)) { return -ENOMEM; }
	unsigned offset = pio_add_program(pio, &program);
	pio_sm_config config = pio_get_default_sm_config();
	sm_config_set_wrap(&config, offset, offset + 2);
	sm_config_set_in_pins(&config, DATA_PIN);
	sm_config_set_sideset(&config, 1, false, false);
	sm_config_set_sideset_pins(&config, CLOCK_PIN);
	sm_config_set_in_shift(&config, true, true, 32);
	sm_config_set_fifo_join(&config, PIO_FIFO_JOIN_RX);
	uint32_t sys_hz = clock_get_hz(clk_sys);
	uint32_t div256 = ((uint64_t)sys_hz * 256u + PDM_CLOCK_HZ * 5u) /
			  (PDM_CLOCK_HZ * 10u);
	sm_config_set_clkdiv_int_frac8(&config, div256 / 256u, div256 % 256u);
	capture_stats.sample_rate = ((uint64_t)sys_hz * 256u + div256 * 5u * PDM_DECIMATION) /
				    (div256 * 10u * PDM_DECIMATION);
	for (unsigned pin = CLOCK_PIN; pin <= DATA_PIN + 3; pin++) {
		pio_gpio_init(pio, pin);
	}
	pio_sm_init(pio, sm, offset, &config);
	pio_sm_set_consecutive_pindirs(pio, sm, CLOCK_PIN, 1, true);
	pio_sm_set_consecutive_pindirs(pio, sm, DATA_PIN, 4, false);
	pio_sm_set_pins_with_mask(pio, sm, 0, BIT(CLOCK_PIN));
	ret = reset_line_toggle_dt(&reset);
	if (ret) { return ret; }
	for (unsigned i = 0; i < 2; i++) {
		channels[i] = dma_claim_unused_channel(false);
		if (channels[i] < 0) { return -EBUSY; }
		ret = allocate_raw(&active[i]);
		if (ret) { return ret; }
		channel_mask |= BIT(channels[i]);
	}
	for (unsigned i = 0; i < 2; i++) {
		dma_channel_config dma_config = dma_channel_get_default_config(channels[i]);
		channel_config_set_transfer_data_size(&dma_config, DMA_SIZE_32);
		channel_config_set_read_increment(&dma_config, false);
		channel_config_set_write_increment(&dma_config, true);
		channel_config_set_ring(&dma_config, true, 12);
		channel_config_set_dreq(&dma_config, pio_get_dreq(pio, sm, false));
		channel_config_set_chain_to(&dma_config, channels[i ^ 1]);
		dma_channel_configure(channels[i], &dma_config, active[i]->words,
				      &pio->rxf[sm], CAPTURE_WORDS, false);
	}
	IRQ_CONNECT(DMA_IRQ, 1, dma_isr, NULL, 0);
	dma_hw->ints2 = channel_mask;
	dma_hw->inte2 |= channel_mask;
	irq_enable(DMA_IRQ);
	pio->fdebug = BIT(PIO_FDEBUG_RXSTALL_LSB + sm);
	dma_start_channel_mask(BIT(channels[0]));
	pio_sm_set_enabled(pio, sm, true);
	return 0;
}

int capture_read(struct capture_block **block, k_timeout_t timeout)
{
	return k_msgq_get(&raw_queue, block, timeout);
}

void capture_release(struct capture_block *block)
{
	k_mem_slab_free(&raw_pool, block);
}

int capture_clock_measure(uint32_t *edges, uint32_t *elapsed_us)
{
	if (!counter_initialized) {
		const struct device *dev = DEVICE_DT_GET(DT_NODELABEL(mic_pio));
		int ret = pio_rpi_pico_allocate_sm(dev, &counter_sm);
		if (ret) { return ret; }
		uint16_t instructions[] = {
			pio_encode_wait_gpio(false, CLOCK_PIN),
			pio_encode_wait_gpio(true, CLOCK_PIN),
			pio_encode_jmp_x_dec(0),
		};
		struct pio_program program = {.instructions = instructions, .length = 3, .origin = -1};
		if (!pio_can_add_program(pio, &program)) {
			pio_sm_unclaim(pio, counter_sm);
			return -ENOMEM;
		}
		counter_offset = pio_add_program(pio, &program);
		counter_initialized = true;
	}
	pio_sm_config config = pio_get_default_sm_config();
	sm_config_set_wrap(&config, counter_offset, counter_offset + 2);
	pio_sm_init(pio, counter_sm, counter_offset, &config);
	pio_sm_clear_fifos(pio, counter_sm);
	pio_sm_restart(pio, counter_sm);
	pio_sm_exec(pio, counter_sm, pio_encode_jmp(counter_offset));
	pio_sm_exec(pio, counter_sm, pio_encode_mov_not(pio_x, pio_null));
	uint32_t start = k_cycle_get_32();
	pio_sm_set_enabled(pio, counter_sm, true);
	k_msleep(20);
	pio_sm_set_enabled(pio, counter_sm, false);
	*elapsed_us = k_cyc_to_us_floor32(k_cycle_get_32() - start);
	pio_sm_exec(pio, counter_sm, pio_encode_mov(pio_isr, pio_x));
	pio_sm_exec(pio, counter_sm, pio_encode_push(false, true));
	*edges = ~pio_sm_get(pio, counter_sm);
	return 0;
}

static int probe_read(const pio_sm_config *config, unsigned offset, uint32_t *words, unsigned count)
{
	pio_sm_init(pio, counter_sm, offset, config);
	int channel = dma_claim_unused_channel(false);
	if (channel < 0) { return -EBUSY; }
	dma_channel_config dma_config = dma_channel_get_default_config(channel);
	channel_config_set_transfer_data_size(&dma_config, DMA_SIZE_32);
	channel_config_set_read_increment(&dma_config, false);
	channel_config_set_write_increment(&dma_config, true);
	channel_config_set_dreq(&dma_config, pio_get_dreq(pio, counter_sm, false));
	dma_channel_configure(channel, &dma_config, words, &pio->rxf[counter_sm], count, true);
	pio_sm_set_enabled(pio, counter_sm, true);
	int64_t deadline = k_uptime_get() + 200;
	while (dma_channel_is_busy(channel) && k_uptime_get() < deadline) { k_msleep(1); }
	bool timed_out = dma_channel_is_busy(channel);
	pio_sm_set_enabled(pio, counter_sm, false);
	dma_channel_cleanup(channel);
	dma_channel_unclaim(channel);
	return timed_out ? -ETIMEDOUT : 0;
}

int capture_phase_read(uint32_t *words, unsigned count)
{
	static bool initialized;
	static unsigned offset;
	if (!counter_initialized) { return -ENODEV; }
	if (!initialized) {
		/* Sample about 100 ns after detecting each falling/rising edge, well
		 * inside the respective half-cycle at the default PDM clock. */
		uint16_t instructions[] = {
			pio_encode_wait_gpio(false, CLOCK_PIN),
			pio_encode_nop() | pio_encode_delay(13),
			pio_encode_in(pio_pins, 4),
			pio_encode_wait_gpio(true, CLOCK_PIN),
			pio_encode_nop() | pio_encode_delay(13),
			pio_encode_in(pio_pins, 4),
		};
		struct pio_program program = {.instructions = instructions, .length = 6, .origin = -1};
		if (!pio_can_add_program(pio, &program)) { return -ENOMEM; }
		offset = pio_add_program(pio, &program);
		initialized = true;
	}
	pio_sm_config config = pio_get_default_sm_config();
	sm_config_set_wrap(&config, offset, offset + 5);
	sm_config_set_in_pins(&config, DATA_PIN);
	sm_config_set_in_shift(&config, true, true, 32);
	sm_config_set_fifo_join(&config, PIO_FIFO_JOIN_RX);
	return probe_read(&config, offset, words, count);
}

int capture_clock_trace(uint32_t *words, unsigned count)
{
	static bool initialized;
	static unsigned offset;
	if (!counter_initialized) { return -ENODEV; }
	if (!initialized) {
		uint16_t instruction = pio_encode_in(pio_pins, 1);
		struct pio_program program = {.instructions = &instruction, .length = 1, .origin = -1};
		if (!pio_can_add_program(pio, &program)) { return -ENOMEM; }
		offset = pio_add_program(pio, &program);
		initialized = true;
	}
	pio_sm_config config = pio_get_default_sm_config();
	sm_config_set_wrap(&config, offset, offset);
	sm_config_set_in_pins(&config, CLOCK_PIN);
	sm_config_set_in_shift(&config, true, true, 32);
	sm_config_set_fifo_join(&config, PIO_FIFO_JOIN_RX);
	return probe_read(&config, offset, words, count);
}
```

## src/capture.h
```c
#ifndef CAPTURE_H
#define CAPTURE_H
#include <zephyr/kernel.h>
#include <zephyr/sys/atomic.h>
#include <stdint.h>
#include "pdm_filter.h"
#define CAPTURE_WORDS (CAPTURE_FRAMES * PDM_WORDS_PER_FRAME)
#define CAPTURE_FRAMES 128
#define CAPTURE_BUFFERS 24
#define PDM_CLOCK_HZ (PCM_SAMPLE_RATE * PDM_DECIMATION)
struct capture_block {
	uint32_t *words; /* Separate aligned 4 KiB DMA area; metadata is never in it. */
	uint32_t sequence;
 uint32_t end_us; /* DMA completion timestamp, before PCM/DSP processing. */
};
struct capture_stats {
	atomic_t blocks;
	atomic_t dropped;
	atomic_t faults;
	uint32_t sample_rate;
};
extern struct capture_stats capture_stats;
int capture_start(void);
void capture_fail(void);
int capture_read(struct capture_block **block, k_timeout_t timeout);
void capture_release(struct capture_block *block);
int capture_clock_measure(uint32_t *edges, uint32_t *elapsed_us);
int capture_phase_read(uint32_t *words, unsigned count);
int capture_clock_trace(uint32_t *words, unsigned count);
#endif
```
